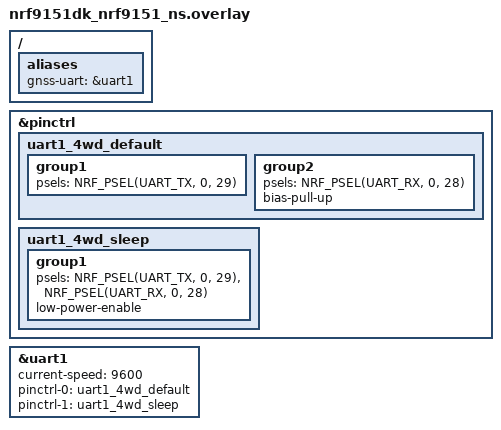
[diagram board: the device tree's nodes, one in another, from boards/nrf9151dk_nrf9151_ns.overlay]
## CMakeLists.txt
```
#
# Copyright (c) 2019 Nordic Semiconductor
#
# SPDX-License-Identifier: LicenseRef-Nordic-5-Clause
#

cmake_minimum_required(VERSION 3.20.0)

find_package(Zephyr REQUIRED HINTS $ENV{ZEPHYR_BASE})
project(gnss_sample)

zephyr_library_sources(src/main.c)
zephyr_library_sources_ifdef(CONFIG_GNSS_SAMPLE_BLE_ENABLED src/gnss_ble.c)
zephyr_library_sources_ifdef(CONFIG_GNSS_SAMPLE_UART_BRIDGE_ENABLED src/gnss_uart_bridge.c)
zephyr_library_sources_ifdef(CONFIG_GNSS_SAMPLE_MQTT_NBIOT_ENABLED src/cloud_config.c)
zephyr_library_sources_ifdef(CONFIG_GNSS_SAMPLE_MQTT_NBIOT_ENABLED src/telemetry_service.c)
zephyr_library_sources_ifdef(CONFIG_GNSS_SAMPLE_MQTT_NBIOT_ENABLED src/mqtt_nbiot_transport.c)
zephyr_library_sources_ifdef(CONFIG_GNSS_SAMPLE_CELLULAR_FALLBACK_ENABLED src/location_service.c)

zephyr_library_sources_ifdef(CONFIG_GNSS_SAMPLE_ASSISTANCE_NRF_CLOUD src/assistance.c)
zephyr_library_sources_ifdef(CONFIG_GNSS_SAMPLE_ASSISTANCE_SUPL src/assistance_supl.c)
zephyr_library_sources_ifdef(CONFIG_GNSS_SAMPLE_ASSISTANCE_MINIMAL src/assistance_minimal.c)
zephyr_library_sources_ifdef(CONFIG_GNSS_SAMPLE_ASSISTANCE_MINIMAL src/mcc_location_table.c)
```

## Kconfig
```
#
# Copyright (c) 2020 Nordic Semiconductor ASA
#
# SPDX-License-Identifier: LicenseRef-Nordic-5-Clause
#

menu "GNSS sample"

choice
	default GNSS_SAMPLE_MODE_CONTINUOUS
	prompt "Select GNSS operation mode"

config GNSS_SAMPLE_MODE_CONTINUOUS
	bool "Continuous tracking"

config GNSS_SAMPLE_MODE_PERIODIC
	bool "Periodic fixes"

config GNSS_SAMPLE_MODE_TTFF_TEST
	bool "Time-to-first-fix (TTFF) test mode"
	select GNSS_SAMPLE_NMEA_ONLY

endchoice

if GNSS_SAMPLE_MODE_PERIODIC

config GNSS_SAMPLE_PERIODIC_INTERVAL
	int "Fix interval for periodic fixes"
	range 10 65535
	default 120
	help
	  Fix interval (in seconds) for periodic fixes.

config GNSS_SAMPLE_PERIODIC_TIMEOUT
	int "Fix timeout for periodic fixes"
	range 0 65535
	default 120
	help
	  Fix timeout (in seconds) for periodic fixes.
	  If set to zero, GNSS is allowed to run indefinitely until a valid PVT estimate is produced.

endif # GNSS_SAMPLE_MODE_PERIODIC

if GNSS_SAMPLE_MODE_TTFF_TEST

config GNSS_SAMPLE_MODE_TTFF_TEST_COLD_START
	bool "Delete GNSS data before each start (cold start)"
	help
	  When enabled, deletes all stored data from GNSS to force a cold start every time GNSS is started.

config GNSS_SAMPLE_MODE_TTFF_TEST_INTERVAL
	int "Time to wait between TTFF tests in seconds"
	range 1 604800
	default 120

endif # GNSS_SAMPLE_MODE_TTFF_TEST

config GNSS_SAMPLE_NMEA_ONLY
	bool "Output only NMEA strings"
	help
	  Outputs only NMEA strings from the GNSS.

endmenu

choice
	default GNSS_SAMPLE_ASSISTANCE_NONE
	prompt "Select whether GNSS assistance is used or not"

config GNSS_SAMPLE_ASSISTANCE_NONE
	bool "Assistance not used"

config GNSS_SAMPLE_ASSISTANCE_NRF_CLOUD
	bool "Use nRF Cloud A-GNSS"
	select NRF_CLOUD_REST
	imply NRF_CLOUD_AGNSS
	select MODEM_JWT
	select MODEM_INFO
	select DATE_TIME

config GNSS_SAMPLE_ASSISTANCE_SUPL
	bool "Use SUPL assistance"
	select SUPL_CLIENT_LIB

config GNSS_SAMPLE_ASSISTANCE_MINIMAL
	bool "Use factory almanac, LTE network time and MCC based location"
	select GNSS_SAMPLE_LTE_ON_DEMAND
	select SETTINGS
	select FCB
	select FLASH
	select FLASH_MAP

endchoice

if !GNSS_SAMPLE_ASSISTANCE_NONE

config GNSS_SAMPLE_LTE_ON_DEMAND
	bool "LTE is activated only when needed to fetch A-GNSS data"
	depends on !NRF_CLOUD_PGPS
	help
	  Activates LTE only when it is needed to fetch A-GNSS data. This is not supported when
	  P-GPS is enabled.

endif # !GNSS_SAMPLE_ASSISTANCE_NONE

if GNSS_SAMPLE_ASSISTANCE_SUPL

config GNSS_SAMPLE_SUPL_HOSTNAME
	string "SUPL server hostname"
	help
	  SUPL server hostname.

config GNSS_SAMPLE_SUPL_PORT
	int "SUPL server port number"
	range 0 65535
	default 7275 if GNSS_SAMPLE_SUPL_SEC_TAG > 0
	default 7276
	help
	  SUPL server port number. The OMA UserPlane Location Protocol (ULP) port number is 7275,
	  but some servers are known to use port 7276 for non-TLS connections.

config GNSS_SAMPLE_SUPL_SEC_TAG
	int "Security tag for connection to the SUPL server"
	range 0 2147483667
	default 0
	help
	  Set a non-zero value to use TLS for connection to the SUPL server. When TLS is enabled,
	  a root CA certificate must be stored on the modem.

endif # GNSS_SAMPLE_ASSISTANCE_SUPL

if GNSS_SAMPLE_MODE_CONTINUOUS

choice
	default GNSS_SAMPLE_POWER_SAVING_DISABLED
	prompt "Select GNSS power saving mode (duty-cycling)"

config GNSS_SAMPLE_POWER_SAVING_DISABLED
	bool "No power saving"

config GNSS_SAMPLE_POWER_SAVING_MODERATE
	bool "Power saving without significant performance degradation"

config GNSS_SAMPLE_POWER_SAVING_HIGH
	bool "Power saving with acceptable performance degradation"

endchoice

endif # GNSS_SAMPLE_MODE_CONTINUOUS

config GNSS_SAMPLE_REFERENCE_LATITUDE
	string "Reference position latitude in decimal degrees"
	help
	  When set, the sample calculates the distance from the reference position for each fix.
	  Given in decimal degrees (DD), for example "61.500000".

config GNSS_SAMPLE_REFERENCE_LONGITUDE
	string "Reference position longitude in decimal degrees"
	help
	  When set, the sample calculates the distance from the reference position for each fix.
	  Given in decimal degrees (DD), for example "23.800000".

config GNSS_SAMPLE_LOW_ACCURACY
	bool "Allow low accuracy fixes"
	help
	  Allows fixes with lower accuracy.

config GNSS_SAMPLE_MIN_SATELLITES_IN_FIX
	int "Minimum satellites used in fix (0 to disable)"
	range 0 32
	default 0
	help
	  Rejects valid fixes that use fewer satellites than this threshold.
	  Set to 0 to disable filtering.

config GNSS_SAMPLE_MAX_HDOP
	int "Maximum HDOP in tenths (0 to disable)"
	range 0 1000
	default 0
	help
	  Rejects valid fixes with HDOP higher than this threshold.
	  Example: value 25 means HDOP <= 2.5 is accepted.
	  Set to 0 to disable filtering.

config GNSS_SAMPLE_BLE_ENABLED
	bool "Enable BLE streaming interface"
	depends on BT_CTLR
	select BT
	select BT_PERIPHERAL
	select BT_GATT_DYNAMIC_DB
	select BT_DEVICE_NAME_DYNAMIC
	help
	  Enables custom BLE service to stream GNSS JSON frames and accept control commands.

if GNSS_SAMPLE_BLE_ENABLED

config GNSS_SAMPLE_BLE_DEVICE_NAME
	string "BLE device name"
	default "GNSS-DK"
	help
	  BLE advertising name presented to mobile applications.

config GNSS_SAMPLE_BLE_STREAM_RATE_HZ
	int "BLE GNSS stream rate (Hz)"
	range 1 5
	default 1
	help
	  Rate of GNSS JSON notifications sent over BLE.

config GNSS_SAMPLE_BLE_TX_QUEUE_LEN
	int "BLE transmit queue length"
	range 2 32
	default 8
	help
	  Number of pending BLE payload slots. Oldest is dropped on overflow.

endif # GNSS_SAMPLE_BLE_ENABLED

config GNSS_SAMPLE_UART_BRIDGE_ENABLED
	bool "Enable UART bridge for external Bluetooth serial module"
	default y
	select SERIAL
	select UART_INTERRUPT_DRIVEN
	help
	  Streams newline-delimited GNSS JSON frames over a secondary UART and
	  accepts simple text commands from an external serial/Bluetooth module.

if GNSS_SAMPLE_UART_BRIDGE_ENABLED

config GNSS_SAMPLE_UART_BRIDGE_STREAM_RATE_HZ
	int "UART bridge GNSS stream rate (Hz)"
	range 1 5
	default 1
	help
	  Rate of GNSS JSON lines sent over the external UART bridge.

endif # GNSS_SAMPLE_UART_BRIDGE_ENABLED

config GNSS_SAMPLE_CONSOLE_OUTPUT_ENABLED
	bool "Enable periodic GNSS console output"
	default y
	help
	  Prints periodic PVT and NMEA data to the USB serial console.

config GNSS_SAMPLE_GNSS_ENABLED
	bool "Enable GNSS modem operation"
	default y
	help
	  Initializes and starts the modem GNSS engine. Disable for a modem-only
	  build that does not consume GNSS PVT or NMEA data.

config GNSS_SAMPLE_MQTT_NBIOT_ENABLED
	bool "Enable NB-IoT MQTT telemetry transport"
	select MQTT_LIB
	select NET_SOCKETS
	select NET_SOCKETS_OFFLOAD
	help
	  Adds a non-blocking NB-IoT MQTT publisher. BLE and UART transports
	  continue independently. MQTT publishes compact JSON from a location
	  priority chain: GNSS first, then cellular fallback, then last known.

config GNSS_SAMPLE_CELLULAR_FALLBACK_ENABLED
	bool "Enable cellular location fallback when GNSS has no valid fix"
	depends on GNSS_SAMPLE_MQTT_NBIOT_ENABLED
	default y
	help
	  Enables cell-tower based location estimation fallback for MQTT
	  telemetry when GNSS has no accepted valid fix. GNSS remains primary.
	  Cellular location is approximate and is marked as source=cellular.

if GNSS_SAMPLE_MQTT_NBIOT_ENABLED

if GNSS_SAMPLE_CELLULAR_FALLBACK_ENABLED

config GNSS_SAMPLE_CELLULAR_LOCATION_REQUEST_INTERVAL_SECONDS
	int "Cellular fallback request interval in seconds"
	range 15 3600
	default 120
	help
	  Minimum interval between new cellular location requests while GNSS
	  fix is not valid. Keeps NB-IoT usage bounded.

config GNSS_SAMPLE_CELLULAR_LOCATION_TIMEOUT_SECONDS
	int "Cellular fallback HTTP request timeout in seconds"
	range 10 300
	default 45
	help
	  Timeout for one cellular location lookup request to the backend API.

config GNSS_SAMPLE_CELLULAR_LOCATION_CELL_COUNT
	int "Cellular fallback requested cell count"
	range 1 15
	default 4
	help
	  Number of cells requested in %NCELLMEAS command before sending
	  data to the backend resolver.

config GNSS_SAMPLE_CELLULAR_LOCATION_API_HOSTNAME
	string "Cellular location backend hostname"
	default "example.com"
	help
	  Backend hostname that resolves cellular measurements into
	  approximate coordinates.

config GNSS_SAMPLE_CELLULAR_LOCATION_API_PORT
	int "Cellular location backend port"
	range 1 65535
	default 80

config GNSS_SAMPLE_CELLULAR_LOCATION_API_PATH
	string "Cellular location backend path"
	default "/api/cell-loc"
	help
	  HTTP path on the backend API endpoint.

config GNSS_SAMPLE_CELLULAR_LOCATION_API_AUTH_HEADER
	string "Optional Authorization header value"
	default ""
	help
	  Optional full Authorization header value, for example:
	  "Bearer eyJ...". Leave empty if not needed.

config GNSS_SAMPLE_CELLULAR_LOCATION_WORKQ_STACK_SIZE
	int "Cellular fallback worker stack size"
	default 4096

endif # GNSS_SAMPLE_CELLULAR_FALLBACK_ENABLED

config GNSS_SAMPLE_MQTT_APN
	string "NB-IoT APN"
	default "internet.m2mportal.de"
	help
	  APN expected for the default PDP context. Set matching LTE_LC/PDN
	  defaults in prj.conf so the modem uses this APN for CID 0.

config GNSS_SAMPLE_MQTT_BROKER_HOSTNAME
	string "MQTT broker hostname"
	default "test.mosquitto.org"
	help
	  MQTT broker hostname for telemetry publishing.

config GNSS_SAMPLE_MQTT_BROKER_PORT
	int "MQTT broker port"
	range 1 65535
	default 8883 if GNSS_SAMPLE_MQTT_TLS_ENABLED
	default 1883

config GNSS_SAMPLE_MQTT_TLS_ENABLED
	bool "Enable MQTT over TLS (MQTTS)"
	default y
	help
	  Enables secure MQTT transport with TLS. Recommended for NB-IoT
	  deployments where plain port 1883 may be filtered.

if GNSS_SAMPLE_MQTT_TLS_ENABLED

config GNSS_SAMPLE_MQTT_TLS_SEC_TAG
	int "Modem security tag for MQTT TLS credentials"
	default 955
	help
	  Security tag where CA certificate chain is stored in modem NVM.

config GNSS_SAMPLE_MQTT_TLS_PROVISION_CA_CERT
	bool "Provision MQTT CA certificate from firmware on boot"
	default y
	help
	  Writes/updates the CA chain in modem key storage before LTE
	  connection starts.

choice GNSS_SAMPLE_MQTT_TLS_CA_CERT_PROFILE
	prompt "MQTT TLS CA certificate profile"
	default GNSS_SAMPLE_MQTT_TLS_CA_CERT_PROFILE_MOSQUITTO
	help
	  Select which CA certificate chain is provisioned when TLS
	  provisioning is enabled.

config GNSS_SAMPLE_MQTT_TLS_CA_CERT_PROFILE_MOSQUITTO
	bool "Mosquitto test broker CA"
	help
	  CA certificate chain matching test.mosquitto.org.

config GNSS_SAMPLE_MQTT_TLS_CA_CERT_PROFILE_ISRG_ROOT_X1
	bool "ISRG Root X1 (Let's Encrypt)"
	help
	  Root CA used by many public MQTT endpoints, including blynk.cloud.

endchoice # GNSS_SAMPLE_MQTT_TLS_CA_CERT_PROFILE

endif # GNSS_SAMPLE_MQTT_TLS_ENABLED

config GNSS_SAMPLE_MQTT_BROKER_FALLBACK_ENABLED
	bool "Enable MQTT broker fallback"
	default y
	help
	  When enabled, firmware switches to a fallback broker after repeated
	  MQTT connect timeouts.

if GNSS_SAMPLE_MQTT_BROKER_FALLBACK_ENABLED

config GNSS_SAMPLE_MQTT_BROKER_FALLBACK_HOSTNAME
	string "Fallback MQTT broker hostname"
	default "broker.hivemq.com"

config GNSS_SAMPLE_MQTT_BROKER_FALLBACK_PORT
	int "Fallback MQTT broker port"
	range 1 65535
	default 8883 if GNSS_SAMPLE_MQTT_TLS_ENABLED
	default 1883

config GNSS_SAMPLE_MQTT_FAILOVER_AFTER_TIMEOUTS
	int "Failover after consecutive MQTT connect timeouts"
	range 1 20
	default 3

endif # GNSS_SAMPLE_MQTT_BROKER_FALLBACK_ENABLED

config GNSS_SAMPLE_MQTT_CLIENT_ID
	string "MQTT client ID"
	default "nrf9151-001"

config GNSS_SAMPLE_MQTT_USERNAME
	string "MQTT username (optional)"
	default ""
	help
	  Optional MQTT username. For Blynk MQTT use "device".

config GNSS_SAMPLE_MQTT_PASSWORD
	string "MQTT password/token (optional)"
	default ""
	help
	  Optional MQTT password/token. Leave empty to disable password auth.

config GNSS_SAMPLE_MQTT_DEVICE_ID
	string "Telemetry device ID"
	default "nrf9151-001"

config GNSS_SAMPLE_MQTT_TOPIC
	string "MQTT telemetry topic"
	default "devices/nrf9151-001/telemetry"

config GNSS_SAMPLE_MQTT_SUBSCRIBE_TOPIC
	string "MQTT subscribe topic (optional)"
	default ""
	help
	  Optional topic subscription for downlink commands, for example
	  "downlink/#" on Blynk MQTT.

config GNSS_SAMPLE_MQTT_RETAIN_MESSAGES
	bool "Publish MQTT telemetry with retain flag"
	default n
	help
	  When enabled, the broker stores the last published telemetry payload
	  on the topic and delivers it immediately to new subscribers.

config GNSS_SAMPLE_MQTT_PUBLISH_INTERVAL_SECONDS
	int "Minimum MQTT publish interval in seconds"
	range 10 86400
	default 60
	help
	  Minimum interval between MQTT publishes. Keep this conservative for
	  limited NB-IoT SIM data volume.

config GNSS_SAMPLE_MQTT_RETRY_BACKOFF_SECONDS
	int "MQTT retry backoff in seconds"
	range 10 3600
	default 60

config GNSS_SAMPLE_MQTT_REGISTRATION_TIMEOUT_SECONDS
	int "NB-IoT registration status log interval in seconds"
	range 10 3600
	default 120

config GNSS_SAMPLE_MQTT_SEARCH_RECOVERY_SECONDS
	int "NB-IoT search recovery interval in seconds"
	range 30 3600
	default 240
	help
	  If LTE remains unregistered/searching for this long, the firmware
	  will trigger an automatic offline/reconnect recovery cycle.

config GNSS_SAMPLE_MQTT_CONNECT_TIMEOUT_SECONDS
	int "MQTT connect timeout in seconds"
	range 10 300
	default 120
	help
	  Time to wait for CONNACK after MQTT connect attempt. NB-IoT links can
	  be higher-latency than Wi-Fi/LTE-M, so use a conservative timeout.

config GNSS_SAMPLE_MQTT_QUEUE_LEN
	int "MQTT telemetry queue length"
	range 1 8
	default 2
	help
	  Number of valid-fix telemetry samples that can wait for MQTT. Oldest
	  samples are dropped on overflow to avoid stale positions.

config GNSS_SAMPLE_MQTT_BATTERY_PERCENT
	int "Static battery percent included in MQTT JSON (-1 disables)"
	range -1 100
	default -1
	help
	  Placeholder for boards without a battery gauge wired yet. Set to -1
	  to omit battery from compact MQTT JSON.

config GNSS_SAMPLE_MQTT_STACK_SIZE
	int "MQTT worker thread stack size"
	default 4096

config GNSS_SAMPLE_MQTT_THREAD_PRIORITY
	int "MQTT worker thread priority"
	default 7

config GNSS_SAMPLE_TELEMETRY_SERVER_HOST
	string "Telemetry server host (UDP/CoAP)"
	default ""
	help
	  Backend host used for low-data request/response telemetry.

config GNSS_SAMPLE_TELEMETRY_SERVER_PORT
	int "Telemetry server port"
	range 1 65535
	default 9000

config GNSS_SAMPLE_TELEMETRY_PROTOCOL
	string "Telemetry protocol"
	default "udp"
	help
	  Supported values in current implementation: udp, coap.

config GNSS_SAMPLE_TELEMETRY_PUBLISH_INTERVAL_SECONDS
	int "Telemetry interval in seconds"
	range 30 86400
	default 600

config GNSS_SAMPLE_GNSS_TIMEOUT_SECONDS
	int "GNSS timeout in seconds"
	range 10 3600
	default 60

config GNSS_SAMPLE_DATA_MODE_DEFAULT
	string "Default data mode"
	default "auto"
	help
	  Supported values: auto, tn_only, ntn_only.

config GNSS_SAMPLE_TN_ENABLED_DEFAULT
	bool "Enable TN by default"
	default y

config GNSS_SAMPLE_NTN_ENABLED_DEFAULT
	bool "Enable NTN fallback by default"
	default y

config GNSS_SAMPLE_TN_UNAVAILABLE_TIMEOUT_SECONDS
	int "TN unavailable timeout in seconds"
	range 60 86400
	default 300
	help
	  TN is considered unavailable when registration/network failures
	  persist this long continuously.

config GNSS_SAMPLE_NTN_MIN_SEND_INTERVAL_SECONDS
	int "Minimum NTN send interval in seconds"
	range 300 2592000
	default 3600
	help
	  Minimum spacing between NTN payload attempts to protect the low
	  monthly NTN quota.

config GNSS_SAMPLE_NTN_MAX_PAYLOAD_BYTES_DEFAULT
	int "Maximum NTN payload size in bytes"
	range 64 512
	default 200

config GNSS_SAMPLE_MONTHLY_NTN_BYTE_LIMIT_DEFAULT
	int "Monthly NTN byte limit"
	range 1024 500000
	default 50000

config GNSS_SAMPLE_CONFIG_VERSION_DEFAULT
	int "Default configuration version"
	range 0 100000
	default 1

config GNSS_SAMPLE_AUTH_TOKEN_DEFAULT
	string "Default auth token/shared secret"
	default ""

config GNSS_SAMPLE_MAX_PAYLOAD_BYTES_DEFAULT
	int "Default max payload bytes"
	range 64 1200
	default 300

config GNSS_SAMPLE_ENABLE_DEBUG_LOGS_DEFAULT
	bool "Enable debug logs by default"
	default n

config GNSS_SAMPLE_MQTT_SYNC_ENABLED
	bool "Enable MQTT retained config sync"
	default y

config GNSS_SAMPLE_MQTT_SYNC_INTERVAL_SECONDS
	int "MQTT config sync interval in seconds"
	range 300 172800
	default 21600

config GNSS_SAMPLE_MQTT_SYNC_FORCE_IN_NTN
	bool "Allow MQTT config sync in NTN mode"
	default n

config GNSS_SAMPLE_NTN_MIN_INTERVAL_SECONDS
	int "Minimum telemetry interval in NTN mode"
	range 300 86400
	default 3600

config GNSS_SAMPLE_TELEMETRY_BACKOFF_BASE_SECONDS
	int "Base backoff for telemetry failures in seconds"
	range 5 3600
	default 60

config GNSS_SAMPLE_TELEMETRY_BACKOFF_MAX_SECONDS
	int "Maximum backoff for telemetry failures in seconds"
	range 10 86400
	default 3600

endif # GNSS_SAMPLE_MQTT_NBIOT_ENABLED

if GNSS_SAMPLE_ASSISTANCE_MINIMAL && GNSS_SAMPLE_LOW_ACCURACY

config GNSS_SAMPLE_ASSISTANCE_REFERENCE_ALT
	int "Reference altitude for 3-sat first fix in meters"
	range -32767 32767
	default -32767
	help
	  Reference altitude for 3-sat first fix in meters above the reference ellipsoid surface.
	  The default value -32767 implies that reference altitude is not injected.

endif # GNSS_SAMPLE_ASSISTANCE_MINIMAL && GNSS_SAMPLE_LOW_ACCURACY

menu "Zephyr Kernel"
source "Kconfig.zephyr"
endmenu

module = GNSS_SAMPLE
module-str = GNSS sample
source "$(ZEPHYR_BASE)/subsys/logging/Kconfig.template.log_config"
```

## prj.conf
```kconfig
#
# Copyright (c) 2019 Nordic Semiconductor ASA
#
# SPDX-License-Identifier: LicenseRef-Nordic-5-Clause
#

# TF-M config
CONFIG_TFM_PROFILE_TYPE_MINIMAL=y

# General
CONFIG_FPU=y
CONFIG_NRF_MODEM_LIB=y
CONFIG_STDOUT_CONSOLE=y
CONFIG_UART_INTERRUPT_DRIVEN=y
CONFIG_PICOLIBC_IO_FLOAT=y
CONFIG_LOG=y
CONFIG_LOG_MODE_IMMEDIATE=y
CONFIG_SNTP=n
CONFIG_REBOOT=y
CONFIG_SETTINGS=y
CONFIG_SETTINGS_NVS=y
CONFIG_NVS=y
CONFIG_FLASH=y
CONFIG_FLASH_MAP=y
CONFIG_PM_PARTITION_SIZE_SETTINGS_STORAGE=0x8000
CONFIG_SHELL=y
CONFIG_SHELL_BACKEND_SERIAL=y
CONFIG_SHELL_CMD_BUFF_SIZE=256

# GNSS sample
CONFIG_GNSS_SAMPLE_ASSISTANCE_NRF_CLOUD=n

# LTE Link Control
CONFIG_LTE_LINK_CONTROL=y
CONFIG_LTE_NETWORK_MODE_NBIOT_GPS=y
CONFIG_LTE_MODE_PREFERENCE_AUTO=y
CONFIG_LTE_LC_SYSTEM_MODE_MODULE=y
CONFIG_LTE_LC_FUNCTIONAL_MODE_MODULE=y
CONFIG_LTE_LC_PDN_MODULE=y
CONFIG_LTE_LC_PDN_DEFAULTS_OVERRIDE=y
CONFIG_LTE_LC_PDN_DEFAULT_APN="internet.m2mportal.de"
CONFIG_LTE_LC_PDN_DEFAULT_FAM_IPV4V6=y
CONFIG_LTE_LC_PSM_MODULE=y
CONFIG_LTE_PSM_REQ=y
# PSM requested periodic TAU 8 hours
CONFIG_LTE_PSM_REQ_RPTAU="00101000"
# PSM requested active time 6 seconds
CONFIG_LTE_PSM_REQ_RAT="00000011"

# The USB VCOM is used by the Zephyr shell for local test commands such as
# `ble_send`.  Keep direct nrf_modem_at_cmd() calls available to the app, but
# do not attach the AT host input handler to this same UART.
CONFIG_AT_HOST_LIBRARY=n

# External serial bridge to the 4WD board Bluetooth module.
CONFIG_GNSS_SAMPLE_UART_BRIDGE_ENABLED=y
CONFIG_GNSS_SAMPLE_CONSOLE_OUTPUT_ENABLED=y
CONFIG_GNSS_SAMPLE_GNSS_ENABLED=y
CONFIG_GNSS_SAMPLE_UART_BRIDGE_STREAM_RATE_HZ=1

# Networking
CONFIG_NETWORKING=y
CONFIG_NET_SOCKETS_OFFLOAD=y
CONFIG_NET_SOCKETS=y
CONFIG_NET_IPV4=y
# Disable native network stack to save some memory
CONFIG_NET_NATIVE=n

# NB-IoT MQTT telemetry transport.
CONFIG_GNSS_SAMPLE_MQTT_NBIOT_ENABLED=n
CONFIG_GNSS_SAMPLE_MQTT_APN="internet.m2mportal.de"
CONFIG_GNSS_SAMPLE_MQTT_BROKER_HOSTNAME="broker.hivemq.com"
CONFIG_GNSS_SAMPLE_MQTT_BROKER_PORT=1883
CONFIG_GNSS_SAMPLE_MQTT_TLS_ENABLED=n
CONFIG_GNSS_SAMPLE_MQTT_BROKER_FALLBACK_ENABLED=n
CONFIG_GNSS_SAMPLE_MQTT_CLIENT_ID="nrf9151-001"
CONFIG_GNSS_SAMPLE_MQTT_USERNAME=""
CONFIG_GNSS_SAMPLE_MQTT_PASSWORD=""
CONFIG_GNSS_SAMPLE_MQTT_DEVICE_ID="nrf9151-001"
CONFIG_GNSS_SAMPLE_MQTT_TOPIC="devices/nrf9151-001/config-sync-unused"
CONFIG_GNSS_SAMPLE_MQTT_RETAIN_MESSAGES=n
CONFIG_GNSS_SAMPLE_MQTT_PUBLISH_INTERVAL_SECONDS=600
CONFIG_GNSS_SAMPLE_MQTT_RETRY_BACKOFF_SECONDS=60
CONFIG_MQTT_KEEPALIVE=120

# Hybrid low-data defaults.
CONFIG_GNSS_SAMPLE_TELEMETRY_SERVER_HOST=""
CONFIG_GNSS_SAMPLE_TELEMETRY_SERVER_PORT=9000
CONFIG_GNSS_SAMPLE_TELEMETRY_PROTOCOL="udp"
CONFIG_GNSS_SAMPLE_TELEMETRY_PUBLISH_INTERVAL_SECONDS=600
CONFIG_GNSS_SAMPLE_GNSS_TIMEOUT_SECONDS=60
CONFIG_GNSS_SAMPLE_DATA_MODE_DEFAULT="auto"
CONFIG_GNSS_SAMPLE_TN_ENABLED_DEFAULT=y
CONFIG_GNSS_SAMPLE_NTN_ENABLED_DEFAULT=y
CONFIG_GNSS_SAMPLE_TN_UNAVAILABLE_TIMEOUT_SECONDS=300
CONFIG_GNSS_SAMPLE_NTN_MIN_SEND_INTERVAL_SECONDS=3600
CONFIG_GNSS_SAMPLE_NTN_MAX_PAYLOAD_BYTES_DEFAULT=200
CONFIG_GNSS_SAMPLE_MONTHLY_NTN_BYTE_LIMIT_DEFAULT=50000
CONFIG_GNSS_SAMPLE_CONFIG_VERSION_DEFAULT=1
CONFIG_GNSS_SAMPLE_AUTH_TOKEN_DEFAULT=""
CONFIG_GNSS_SAMPLE_MAX_PAYLOAD_BYTES_DEFAULT=300
CONFIG_GNSS_SAMPLE_ENABLE_DEBUG_LOGS_DEFAULT=n
CONFIG_GNSS_SAMPLE_MQTT_SYNC_ENABLED=n
CONFIG_GNSS_SAMPLE_MQTT_SYNC_INTERVAL_SECONDS=21600
CONFIG_GNSS_SAMPLE_MQTT_SYNC_FORCE_IN_NTN=n
CONFIG_GNSS_SAMPLE_TELEMETRY_BACKOFF_BASE_SECONDS=60
CONFIG_GNSS_SAMPLE_TELEMETRY_BACKOFF_MAX_SECONDS=3600

# OpenCellID/cellular resolver fallback removed.
CONFIG_GNSS_SAMPLE_CELLULAR_FALLBACK_ENABLED=n

# Memory and stack configuration
CONFIG_HEAP_MEM_POOL_SIZE=8192
CONFIG_MAIN_STACK_SIZE=4096
CONFIG_SYSTEM_WORKQUEUE_STACK_SIZE=1536
```

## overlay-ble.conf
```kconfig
#
# BLE streaming overlay for BLE-capable Nordic boards.
# Example:
# west build -b nrf52840dk/nrf52840 -- -DEXTRA_CONF_FILE=overlay-ble.conf
#

CONFIG_GNSS_SAMPLE_BLE_ENABLED=y
CONFIG_GNSS_SAMPLE_BLE_DEVICE_NAME="GNSS-DK"
CONFIG_GNSS_SAMPLE_BLE_STREAM_RATE_HZ=1
CONFIG_GNSS_SAMPLE_BLE_TX_QUEUE_LEN=8

CONFIG_BT=y
CONFIG_BT_PERIPHERAL=y
CONFIG_BT_DEVICE_NAME_DYNAMIC=y
CONFIG_BT_MAX_CONN=1
CONFIG_BT_SETTINGS=y
CONFIG_SETTINGS=y
CONFIG_BT_SMP=y
CONFIG_BT_SIGNING=n
CONFIG_BT_GATT_CLIENT=n
CONFIG_BT_CTLR_PHY_2M=n
```

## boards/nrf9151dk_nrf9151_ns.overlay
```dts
/* Route the application UART bridge to the nRF9151 SMA DK header pins.
 * Wire P0.29/TX to the 4WD board Bluetooth RX net, and P0.28/RX to Bluetooth TX.
 */

/ {
	aliases {
		gnss-uart = &uart1;
	};
};

&pinctrl {
	uart1_4wd_default: uart1_4wd_default {
		group1 {
			psels = <NRF_PSEL(UART_TX, 0, 29)>;
		};

		group2 {
			psels = <NRF_PSEL(UART_RX, 0, 28)>;
			bias-pull-up;
		};
	};

	uart1_4wd_sleep: uart1_4wd_sleep {
		group1 {
			psels = <NRF_PSEL(UART_TX, 0, 29)>,
				<NRF_PSEL(UART_RX, 0, 28)>;
			low-power-enable;
		};
	};
};

&uart1 {
	status = "okay";
	current-speed = <9600>;
	pinctrl-0 = <&uart1_4wd_default>;
	pinctrl-1 = <&uart1_4wd_sleep>;
	pinctrl-names = "default", "sleep";
};
```

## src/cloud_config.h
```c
/*
 * Copyright (c) 2026
 *
 * SPDX-License-Identifier: LicenseRef-Nordic-5-Clause
 */

#ifndef CLOUD_CONFIG_H_
#define CLOUD_CONFIG_H_

#include <stdbool.h>
#include <stdint.h>
#include <modem/lte_lc.h>

#ifdef __cplusplus
extern "C" {
#endif

#define CLOUD_CONFIG_DEVICE_ID_MAX_LEN 64
#define CLOUD_CONFIG_HOST_MAX_LEN 96
#define CLOUD_CONFIG_PROTOCOL_MAX_LEN 8
#define CLOUD_CONFIG_TOPIC_MAX_LEN 128
#define CLOUD_CONFIG_USERNAME_MAX_LEN 64
#define CLOUD_CONFIG_PASSWORD_MAX_LEN 128
#define CLOUD_CONFIG_TOKEN_MAX_LEN 128
#define CLOUD_CONFIG_APN_MAX_LEN 64
#define CLOUD_CONFIG_LTE_MODE_MAX_LEN 32
#define CLOUD_CONFIG_DATA_MODE_MAX_LEN 16

struct cloud_runtime_config {
	char device_id[CLOUD_CONFIG_DEVICE_ID_MAX_LEN];
	char server_host[CLOUD_CONFIG_HOST_MAX_LEN];
	uint16_t server_port;
	char protocol[CLOUD_CONFIG_PROTOCOL_MAX_LEN];
	char telemetry_protocol[CLOUD_CONFIG_PROTOCOL_MAX_LEN];
	uint32_t publish_interval_sec;
	uint32_t gnss_timeout_sec;
	char data_mode[CLOUD_CONFIG_DATA_MODE_MAX_LEN];
	bool tn_enabled;
	bool ntn_enabled;
	uint32_t tn_unavailable_timeout_sec;
	uint32_t ntn_min_send_interval_sec;
	uint16_t ntn_max_payload_bytes;
	uint32_t monthly_ntn_byte_limit;
	uint32_t config_version;
	char auth_token[CLOUD_CONFIG_TOKEN_MAX_LEN];
	uint16_t max_payload_bytes;
	bool enable_debug_logs;

	char mqtt_host[CLOUD_CONFIG_HOST_MAX_LEN];
	uint16_t mqtt_port;
	char mqtt_username[CLOUD_CONFIG_USERNAME_MAX_LEN];
	char mqtt_password[CLOUD_CONFIG_PASSWORD_MAX_LEN];
	int32_t mqtt_tls_sec_tag;
	uint32_t mqtt_sync_interval_sec;
	bool mqtt_sync_enabled;
	bool mqtt_sync_force_in_ntn;

	char apn[CLOUD_CONFIG_APN_MAX_LEN];
	char lte_mode[CLOUD_CONFIG_LTE_MODE_MAX_LEN];
};

int cloud_config_init(void);
const struct cloud_runtime_config *cloud_config_get(void);
const char *cloud_config_device_id_get(void);

int cloud_config_set(const char *key, const char *value);
int cloud_config_save(void);
bool cloud_config_is_dirty(void);
bool cloud_config_reboot_required(void);

int cloud_config_get_lte_mode(enum lte_lc_system_mode *mode,
			      enum lte_lc_system_mode_preference *pref);

int cloud_config_apply_mqtt_retained(const char *json, size_t len, bool *applied_newer);

#ifdef __cplusplus
}
#endif

#endif /* CLOUD_CONFIG_H_ */
```

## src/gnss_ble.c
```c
/*
 * Copyright (c) 2026
 *
 * SPDX-License-Identifier: LicenseRef-Nordic-5-Clause
 */

#include "gnss_ble.h"

#include <stdio.h>
#include <stdlib.h>
#include <string.h>
#include <zephyr/kernel.h>
#include <zephyr/sys/atomic.h>
#include <zephyr/sys/util.h>
#include <zephyr/logging/log.h>
#include <zephyr/bluetooth/bluetooth.h>
#include <zephyr/bluetooth/conn.h>
#include <zephyr/bluetooth/gatt.h>
#include <zephyr/bluetooth/uuid.h>
#include <zephyr/settings/settings.h>

LOG_MODULE_DECLARE(gnss_sample, CONFIG_GNSS_SAMPLE_LOG_LEVEL);

#define GNSS_BLE_JSON_BUF_LEN 768
#define GNSS_BLE_CMD_MAX_LEN 64

/* 6b6f6f00-39f0-4d47-9c30-47c0c53b3d01 */
#define BT_UUID_GNSS_SERVICE_VAL \
	BT_UUID_128_ENCODE(0x6b6f6f00, 0x39f0, 0x4d47, 0x9c30, 0x47c0c53b3d01)
/* 6b6f6f01-39f0-4d47-9c30-47c0c53b3d01 */
#define BT_UUID_GNSS_TX_VAL \
	BT_UUID_128_ENCODE(0x6b6f6f01, 0x39f0, 0x4d47, 0x9c30, 0x47c0c53b3d01)
/* 6b6f6f02-39f0-4d47-9c30-47c0c53b3d01 */
#define BT_UUID_GNSS_RX_VAL \
	BT_UUID_128_ENCODE(0x6b6f6f02, 0x39f0, 0x4d47, 0x9c30, 0x47c0c53b3d01)

static struct bt_uuid_128 gnss_service_uuid = BT_UUID_INIT_128(BT_UUID_GNSS_SERVICE_VAL);
static struct bt_uuid_128 gnss_tx_uuid = BT_UUID_INIT_128(BT_UUID_GNSS_TX_VAL);
static struct bt_uuid_128 gnss_rx_uuid = BT_UUID_INIT_128(BT_UUID_GNSS_RX_VAL);

static struct bt_conn *current_conn;
static atomic_t notify_enabled;
static atomic_t stream_enabled = ATOMIC_INIT(1);
static atomic_t stream_rate_hz = ATOMIC_INIT(CONFIG_GNSS_SAMPLE_BLE_STREAM_RATE_HZ);
static atomic_t ble_dropped;

static char last_gga[NRF_MODEM_GNSS_NMEA_MAX_LEN];
static char last_rmc[NRF_MODEM_GNSS_NMEA_MAX_LEN];

struct ble_line {
	char data[GNSS_BLE_JSON_BUF_LEN];
};

K_MSGQ_DEFINE(ble_tx_queue, sizeof(struct ble_line), CONFIG_GNSS_SAMPLE_BLE_TX_QUEUE_LEN, 4);
static struct k_work ble_tx_work;

static struct bt_conn_cb conn_callbacks;

static ssize_t gnss_rx_write(struct bt_conn *conn,
			     const struct bt_gatt_attr *attr,
			     const void *buf,
			     uint16_t len,
			     uint16_t offset,
			     uint8_t flags);
static void ccc_cfg_changed(const struct bt_gatt_attr *attr, uint16_t value);

BT_GATT_SERVICE_DEFINE(gnss_service,
	BT_GATT_PRIMARY_SERVICE(&gnss_service_uuid),
	BT_GATT_CHARACTERISTIC(&gnss_tx_uuid.uuid,
			       BT_GATT_CHRC_NOTIFY,
			       BT_GATT_PERM_NONE,
			       NULL, NULL, NULL),
	BT_GATT_CCC(ccc_cfg_changed,
		    BT_GATT_PERM_READ | BT_GATT_PERM_WRITE),
	BT_GATT_CHARACTERISTIC(&gnss_rx_uuid.uuid,
			       BT_GATT_CHRC_WRITE | BT_GATT_CHRC_WRITE_WITHOUT_RESP,
			       BT_GATT_PERM_WRITE_ENCRYPT,
			       NULL, gnss_rx_write, NULL),
);

static void ccc_cfg_changed(const struct bt_gatt_attr *attr, uint16_t value)
{
	ARG_UNUSED(attr);

	atomic_set(&notify_enabled, (value == BT_GATT_CCC_NOTIFY) ? 1 : 0);
	LOG_INF("BLE notifications %s", atomic_get(&notify_enabled) ? "enabled" : "disabled");
}

static int ble_enqueue_line(const char *line)
{
	struct ble_line item = { 0 };
	size_t copy_len = MIN(strlen(line), sizeof(item.data) - 1U);
	memcpy(item.data, line, copy_len);

	int err = k_msgq_put(&ble_tx_queue, &item, K_NO_WAIT);
	if (err) {
		struct ble_line dropped;
		if (k_msgq_get(&ble_tx_queue, &dropped, K_NO_WAIT) == 0) {
			atomic_inc(&ble_dropped);
			(void)k_msgq_put(&ble_tx_queue, &item, K_NO_WAIT);
		}
	}

	k_work_submit(&ble_tx_work);
	return 0;
}

static void ble_tx_work_fn(struct k_work *work)
{
	ARG_UNUSED(work);

	if (!current_conn || !atomic_get(&notify_enabled) || !atomic_get(&stream_enabled)) {
		return;
	}

	struct ble_line item;
	while (k_msgq_get(&ble_tx_queue, &item, K_NO_WAIT) == 0) {
		int err = bt_gatt_notify(current_conn, &gnss_service.attrs[2], item.data,
					 strlen(item.data));
		if (err) {
			LOG_WRN("BLE notify failed: %d", err);
			break;
		}
	}
}

static void connected(struct bt_conn *conn, uint8_t err)
{
	if (err) {
		LOG_WRN("BLE connect failed: %u", err);
		return;
	}

	current_conn = bt_conn_ref(conn);
	LOG_INF("BLE connected");
	(void)bt_conn_set_security(conn, BT_SECURITY_L2);
}

static void disconnected(struct bt_conn *conn, uint8_t reason)
{
	ARG_UNUSED(reason);

	if (current_conn) {
		bt_conn_unref(current_conn);
		current_conn = NULL;
	}

	atomic_clear(&notify_enabled);
	LOG_INF("BLE disconnected");
}

static bool nmea_is_sentence(const char *line, const char *prefix)
{
	return (strncmp(line, prefix, strlen(prefix)) == 0);
}

static bool pvt_datetime_valid(const struct nrf_modem_gnss_datetime *datetime)
{
	return datetime &&
	       datetime->year >= 2024 &&
	       datetime->month >= 1 && datetime->month <= 12 &&
	       datetime->day >= 1 && datetime->day <= 31 &&
	       datetime->hour <= 23 &&
	       datetime->minute <= 59 &&
	       datetime->seconds <= 60;
}

void gnss_ble_set_last_nmea(const struct nrf_modem_gnss_nmea_data_frame *nmea)
{
	if (!nmea) {
		return;
	}

	if (nmea_is_sentence(nmea->nmea_str, "$GPGGA") || nmea_is_sentence(nmea->nmea_str, "$GNGGA")) {
		strncpy(last_gga, nmea->nmea_str, sizeof(last_gga) - 1U);
		last_gga[sizeof(last_gga) - 1U] = '\0';
	} else if (nmea_is_sentence(nmea->nmea_str, "$GPRMC") ||
		   nmea_is_sentence(nmea->nmea_str, "$GNRMC")) {
		strncpy(last_rmc, nmea->nmea_str, sizeof(last_rmc) - 1U);
		last_rmc[sizeof(last_rmc) - 1U] = '\0';
	}
}

static ssize_t gnss_rx_write(struct bt_conn *conn,
			     const struct bt_gatt_attr *attr,
			     const void *buf,
			     uint16_t len,
			     uint16_t offset,
			     uint8_t flags)
{
	ARG_UNUSED(conn);
	ARG_UNUSED(attr);
	ARG_UNUSED(offset);
	ARG_UNUSED(flags);

	char cmd[GNSS_BLE_CMD_MAX_LEN] = {0};
	size_t copy = MIN((size_t)len, sizeof(cmd) - 1U);
	memcpy(cmd, buf, copy);

	if (strcmp(cmd, "START_STREAM") == 0) {
		atomic_set(&stream_enabled, 1);
		gnss_ble_notify_status("STREAM_STARTED", "Streaming enabled", "");
		return len;
	}

	if (strcmp(cmd, "STOP_STREAM") == 0) {
		atomic_set(&stream_enabled, 0);
		gnss_ble_notify_status("STREAM_STOPPED", "Streaming disabled", "");
		return len;
	}

	if (strncmp(cmd, "SET_RATE:", 9) == 0) {
		long rate = strtol(cmd + 9, NULL, 10);
		if (rate >= 1 && rate <= 5) {
			atomic_set(&stream_rate_hz, (int)rate);
			gnss_ble_notify_status("RATE_UPDATED", "Stream rate updated", cmd + 9);
		} else {
			gnss_ble_notify_status("INVALID_RATE", "SET_RATE must be between 1 and 5",
					       cmd + 9);
		}
		return len;
	}

	if (strcmp(cmd, "REQUEST_STATUS") == 0) {
		gnss_ble_notify_status("STATUS", "Status requested", "");
		return len;
	}

	gnss_ble_notify_status("UNKNOWN_COMMAND", "Unsupported command", cmd);
	return len;
}

void gnss_ble_notify_status(const char *code, const char *message, const char *details)
{
	char buf[GNSS_BLE_JSON_BUF_LEN];
	snprintk(buf, sizeof(buf),
		 "{\"type\":\"status\",\"code\":\"%s\",\"message\":\"%s\",\"details\":\"%s\"}\n",
		 code ? code : "", message ? message : "", details ? details : "");
	(void)ble_enqueue_line(buf);
}

void gnss_ble_notify_pvt(const struct nrf_modem_gnss_pvt_data_frame *pvt,
			 uint8_t tracked,
			 uint8_t used,
			 uint8_t unhealthy,
			 const struct gnss_ble_metrics *metrics)
{
	static int64_t last_sent_ms;
	int hz = atomic_get(&stream_rate_hz);
	int64_t now_ms = k_uptime_get();
	int64_t min_period = 1000 / MAX(hz, 1);

	if (!pvt || !atomic_get(&stream_enabled)) {
		return;
	}

	if ((now_ms - last_sent_ms) < min_period) {
		return;
	}

	last_sent_ms = now_ms;

	char json[GNSS_BLE_JSON_BUF_LEN];
	bool valid = (pvt->flags & NRF_MODEM_GNSS_PVT_FLAG_FIX_VALID) != 0;
	uint32_t accepted = metrics ? metrics->fixes_accepted : 0U;
	uint32_t rejected = metrics ? metrics->fixes_rejected : 0U;
	uint32_t nmea_d = metrics ? metrics->nmea_dropped : 0U;
	char timestamp[25] = {0};
	bool have_timestamp = false;

	if (pvt_datetime_valid(&pvt->datetime)) {
		snprintk(timestamp, sizeof(timestamp),
			 "%04u-%02u-%02uT%02u:%02u:%02uZ",
			 pvt->datetime.year, pvt->datetime.month, pvt->datetime.day,
			 pvt->datetime.hour, pvt->datetime.minute, pvt->datetime.seconds);
		have_timestamp = true;
	}

	if (valid) {
		if (have_timestamp) {
			snprintk(json, sizeof(json),
				 "{\"ts_ms\":%lld,\"timestamp\":\"%s\",\"fix_valid\":true,"
				 "\"lat\":%.06f,\"lon\":%.06f,\"accuracy_m\":%.01f,"
				 "\"alt_m\":%.01f,\"alt_acc_m\":%.01f,"
				 "\"speed_mps\":%.01f,\"speed_acc_mps\":%.01f,"
				 "\"v_speed_mps\":%.01f,\"v_speed_acc_mps\":%.01f,"
				 "\"heading_deg\":%.01f,\"heading_acc_deg\":%.01f,"
				 "\"pdop\":%.01f,\"hdop\":%.01f,\"vdop\":%.01f,\"tdop\":%.01f,"
				 "\"tracked\":%u,\"used\":%u,\"unhealthy\":%u,"
				 "\"nmea_gga\":\"%s\",\"nmea_rmc\":\"%s\","
				 "\"counters\":{\"accepted\":%u,\"rejected\":%u,\"nmea_dropped\":%u,"
				 "\"ble_dropped\":%u}}\n",
				 now_ms, timestamp,
				 pvt->latitude, pvt->longitude, (double)pvt->accuracy,
				 (double)pvt->altitude, (double)pvt->altitude_accuracy,
				 (double)pvt->speed, (double)pvt->speed_accuracy,
				 (double)pvt->vertical_speed, (double)pvt->vertical_speed_accuracy,
				 (double)pvt->heading, (double)pvt->heading_accuracy,
				 (double)pvt->pdop, (double)pvt->hdop, (double)pvt->vdop, (double)pvt->tdop,
				 tracked, used, unhealthy,
				 last_gga, last_rmc, accepted, rejected, nmea_d,
				 (uint32_t)atomic_get(&ble_dropped));
		} else {
			snprintk(json, sizeof(json),
				 "{\"ts_ms\":%lld,\"fix_valid\":true,\"lat\":%.06f,\"lon\":%.06f,"
				 "\"accuracy_m\":%.01f,\"alt_m\":%.01f,\"alt_acc_m\":%.01f,"
				 "\"speed_mps\":%.01f,\"speed_acc_mps\":%.01f,"
				 "\"v_speed_mps\":%.01f,\"v_speed_acc_mps\":%.01f,"
				 "\"heading_deg\":%.01f,\"heading_acc_deg\":%.01f,"
				 "\"pdop\":%.01f,\"hdop\":%.01f,\"vdop\":%.01f,\"tdop\":%.01f,"
				 "\"tracked\":%u,\"used\":%u,\"unhealthy\":%u,"
				 "\"nmea_gga\":\"%s\",\"nmea_rmc\":\"%s\","
				 "\"counters\":{\"accepted\":%u,\"rejected\":%u,\"nmea_dropped\":%u,"
				 "\"ble_dropped\":%u}}\n",
				 now_ms,
				 pvt->latitude, pvt->longitude, (double)pvt->accuracy,
				 (double)pvt->altitude, (double)pvt->altitude_accuracy,
				 (double)pvt->speed, (double)pvt->speed_accuracy,
				 (double)pvt->vertical_speed, (double)pvt->vertical_speed_accuracy,
				 (double)pvt->heading, (double)pvt->heading_accuracy,
				 (double)pvt->pdop, (double)pvt->hdop, (double)pvt->vdop, (double)pvt->tdop,
				 tracked, used, unhealthy,
				 last_gga, last_rmc, accepted, rejected, nmea_d,
				 (uint32_t)atomic_get(&ble_dropped));
		}
	} else {
		if (have_timestamp) {
			snprintk(json, sizeof(json),
				 "{\"ts_ms\":%lld,\"timestamp\":\"%s\",\"fix_valid\":false,"
				 "\"lat\":null,\"lon\":null,\"alt_m\":null,"
				 "\"accuracy_m\":%.01f,\"alt_acc_m\":%.01f,"
				 "\"speed_mps\":%.01f,\"speed_acc_mps\":%.01f,"
				 "\"v_speed_mps\":%.01f,\"v_speed_acc_mps\":%.01f,"
				 "\"heading_deg\":%.01f,\"heading_acc_deg\":%.01f,"
				 "\"pdop\":%.01f,\"hdop\":%.01f,\"vdop\":%.01f,\"tdop\":%.01f,"
				 "\"tracked\":%u,\"used\":%u,\"unhealthy\":%u,"
				 "\"nmea_gga\":\"%s\",\"nmea_rmc\":\"%s\","
				 "\"counters\":{\"accepted\":%u,\"rejected\":%u,\"nmea_dropped\":%u,"
				 "\"ble_dropped\":%u}}\n",
				 now_ms, timestamp,
				 (double)pvt->accuracy, (double)pvt->altitude_accuracy,
				 (double)pvt->speed, (double)pvt->speed_accuracy,
				 (double)pvt->vertical_speed, (double)pvt->vertical_speed_accuracy,
				 (double)pvt->heading, (double)pvt->heading_accuracy,
				 (double)pvt->pdop, (double)pvt->hdop, (double)pvt->vdop, (double)pvt->tdop,
				 tracked, used, unhealthy,
				 last_gga, last_rmc, accepted, rejected, nmea_d,
				 (uint32_t)atomic_get(&ble_dropped));
		} else {
			snprintk(json, sizeof(json),
				 "{\"ts_ms\":%lld,\"fix_valid\":false,\"lat\":null,\"lon\":null,\"alt_m\":null,"
				 "\"accuracy_m\":%.01f,\"alt_acc_m\":%.01f,"
				 "\"speed_mps\":%.01f,\"speed_acc_mps\":%.01f,"
				 "\"v_speed_mps\":%.01f,\"v_speed_acc_mps\":%.01f,"
				 "\"heading_deg\":%.01f,\"heading_acc_deg\":%.01f,"
				 "\"pdop\":%.01f,\"hdop\":%.01f,\"vdop\":%.01f,\"tdop\":%.01f,"
				 "\"tracked\":%u,\"used\":%u,\"unhealthy\":%u,"
				 "\"nmea_gga\":\"%s\",\"nmea_rmc\":\"%s\","
				 "\"counters\":{\"accepted\":%u,\"rejected\":%u,\"nmea_dropped\":%u,"
				 "\"ble_dropped\":%u}}\n",
				 now_ms,
				 (double)pvt->accuracy, (double)pvt->altitude_accuracy,
				 (double)pvt->speed, (double)pvt->speed_accuracy,
				 (double)pvt->vertical_speed, (double)pvt->vertical_speed_accuracy,
				 (double)pvt->heading, (double)pvt->heading_accuracy,
				 (double)pvt->pdop, (double)pvt->hdop, (double)pvt->vdop, (double)pvt->tdop,
				 tracked, used, unhealthy,
				 last_gga, last_rmc, accepted, rejected, nmea_d,
				 (uint32_t)atomic_get(&ble_dropped));
		}
	}

	(void)ble_enqueue_line(json);
}

bool gnss_ble_stream_enabled(void)
{
	return atomic_get(&stream_enabled) != 0;
}

uint8_t gnss_ble_stream_rate_hz(void)
{
	return (uint8_t)atomic_get(&stream_rate_hz);
}

uint32_t gnss_ble_dropped_count(void)
{
	return (uint32_t)atomic_get(&ble_dropped);
}

int gnss_ble_init(void)
{
	int err;

	conn_callbacks.connected = connected;
	conn_callbacks.disconnected = disconnected;
	bt_conn_cb_register(&conn_callbacks);
	k_work_init(&ble_tx_work, ble_tx_work_fn);

	err = bt_enable(NULL);
	if (err) {
		LOG_ERR("Failed to enable BLE: %d", err);
		return err;
	}

	if (IS_ENABLED(CONFIG_SETTINGS)) {
		settings_load();
	}

	err = bt_set_name(CONFIG_GNSS_SAMPLE_BLE_DEVICE_NAME);
	if (err) {
		LOG_WRN("Failed to set BLE name: %d", err);
	}

	const struct bt_data ad[] = {
		BT_DATA_BYTES(BT_DATA_FLAGS, (BT_LE_AD_GENERAL | BT_LE_AD_NO_BREDR)),
		BT_DATA_BYTES(BT_DATA_UUID128_ALL, BT_UUID_GNSS_SERVICE_VAL),
	};
	const struct bt_data sd[] = {
		BT_DATA(BT_DATA_NAME_COMPLETE, CONFIG_GNSS_SAMPLE_BLE_DEVICE_NAME,
			sizeof(CONFIG_GNSS_SAMPLE_BLE_DEVICE_NAME) - 1),
	};

	err = bt_le_adv_start(BT_LE_ADV_CONN_FAST_1, ad, ARRAY_SIZE(ad), sd, ARRAY_SIZE(sd));
	if (err) {
		LOG_ERR("Failed to start BLE advertising: %d", err);
		return err;
	}

	LOG_INF("BLE advertising started as %s", CONFIG_GNSS_SAMPLE_BLE_DEVICE_NAME);
	return 0;
}
```

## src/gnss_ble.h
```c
/*
 * Copyright (c) 2026
 *
 * SPDX-License-Identifier: LicenseRef-Nordic-5-Clause
 */

#ifndef GNSS_BLE_H_
#define GNSS_BLE_H_

#include <stdint.h>
#include <stdbool.h>
#include <nrf_modem_gnss.h>

#ifdef __cplusplus
extern "C" {
#endif

struct gnss_ble_metrics {
	uint32_t fixes_accepted;
	uint32_t fixes_rejected;
	uint32_t nmea_dropped;
};

int gnss_ble_init(void);

void gnss_ble_set_last_nmea(const struct nrf_modem_gnss_nmea_data_frame *nmea);

void gnss_ble_notify_pvt(const struct nrf_modem_gnss_pvt_data_frame *pvt,
			 uint8_t tracked,
			 uint8_t used,
			 uint8_t unhealthy,
			 const struct gnss_ble_metrics *metrics);

void gnss_ble_notify_status(const char *code, const char *message, const char *details);

bool gnss_ble_stream_enabled(void);
uint8_t gnss_ble_stream_rate_hz(void);
uint32_t gnss_ble_dropped_count(void);

#ifdef __cplusplus
}
#endif

#endif /* GNSS_BLE_H_ */
```

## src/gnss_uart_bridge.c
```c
/*
 * Copyright (c) 2026
 *
 * SPDX-License-Identifier: LicenseRef-Nordic-5-Clause
 */

#include "gnss_uart_bridge.h"

#include <stdio.h>
#include <stdlib.h>
#include <string.h>
#include <zephyr/device.h>
#include <zephyr/drivers/uart.h>
#include <zephyr/kernel.h>
#include <zephyr/logging/log.h>
#include <zephyr/sys/atomic.h>
#include <zephyr/sys/util.h>

LOG_MODULE_DECLARE(gnss_sample, CONFIG_GNSS_SAMPLE_LOG_LEVEL);

#define GNSS_UART_NODE DT_ALIAS(gnss_uart)

#if !DT_NODE_HAS_STATUS(GNSS_UART_NODE, okay)
#error "GNSS UART bridge requires a devicetree alias named gnss-uart"
#endif

#define JSON_BUF_LEN 512
#define CMD_BUF_LEN 64

static const struct device *const bridge_uart = DEVICE_DT_GET(GNSS_UART_NODE);

struct uart_cmd {
	char data[CMD_BUF_LEN];
};

static atomic_t stream_enabled = ATOMIC_INIT(1);
static atomic_t stream_rate_hz = ATOMIC_INIT(CONFIG_GNSS_SAMPLE_UART_BRIDGE_STREAM_RATE_HZ);
static atomic_t rx_command_count;
static atomic_t rx_overflow_count;

static char last_gga[NRF_MODEM_GNSS_NMEA_MAX_LEN];
static char last_rmc[NRF_MODEM_GNSS_NMEA_MAX_LEN];
static char rx_line[CMD_BUF_LEN];
static size_t rx_line_len;
static int64_t last_publish_ms;

K_MSGQ_DEFINE(uart_cmd_queue, sizeof(struct uart_cmd), 4, 4);
static struct k_work uart_cmd_work;

static void uart_write_str(const char *s)
{
	while (*s != '\0') {
		uart_poll_out(bridge_uart, *s++);
	}
}

static void json_append_escaped(char *buf, size_t len, const char *value)
{
	size_t used = strnlen(buf, len);

	if (used >= len) {
		return;
	}

	for (const char *p = value; *p != '\0'; ++p) {
		if (used >= len - 1U) {
			return;
		}

		if (*p == '\\' || *p == '"') {
			if (used < len - 2U) {
				buf[used++] = '\\';
				buf[used++] = *p;
				buf[used] = '\0';
			}
		} else if (*p == '\r') {
			continue;
		} else if (*p == '\n') {
			continue;
		} else {
			buf[used++] = *p;
			buf[used] = '\0';
		}
	}
}

static bool nmea_is_sentence(const char *line, const char *prefix)
{
	return strncmp(line, prefix, strlen(prefix)) == 0;
}

void gnss_uart_bridge_set_last_nmea(const struct nrf_modem_gnss_nmea_data_frame *nmea)
{
	if (!nmea) {
		return;
	}

	if (nmea_is_sentence(nmea->nmea_str, "$GPGGA") ||
	    nmea_is_sentence(nmea->nmea_str, "$GNGGA")) {
		strncpy(last_gga, nmea->nmea_str, sizeof(last_gga) - 1U);
		last_gga[sizeof(last_gga) - 1U] = '\0';
	} else if (nmea_is_sentence(nmea->nmea_str, "$GPRMC") ||
		   nmea_is_sentence(nmea->nmea_str, "$GNRMC")) {
		strncpy(last_rmc, nmea->nmea_str, sizeof(last_rmc) - 1U);
		last_rmc[sizeof(last_rmc) - 1U] = '\0';
	}
}

static void append_optional_nmea(char *json, size_t len)
{
	if (last_gga[0] != '\0') {
		strncat(json, ",\"nmea_gga\":\"", len - strlen(json) - 1U);
		json_append_escaped(json, len, last_gga);
		strncat(json, "\"", len - strlen(json) - 1U);
	}

	if (last_rmc[0] != '\0') {
		strncat(json, ",\"nmea_rmc\":\"", len - strlen(json) - 1U);
		json_append_escaped(json, len, last_rmc);
		strncat(json, "\"", len - strlen(json) - 1U);
	}
}

void gnss_uart_bridge_publish_status(const char *code, const char *message, const char *details)
{
	char json[JSON_BUF_LEN];

	snprintk(json, sizeof(json),
		 "{\"type\":\"status\",\"ts_ms\":%lld,\"code\":\"%s\",\"message\":\"%s\",\"details\":\"",
		 k_uptime_get(), code ? code : "", message ? message : "");
	json_append_escaped(json, sizeof(json), details ? details : "");
	strncat(json, "\"}\n", sizeof(json) - strlen(json) - 1U);
	uart_write_str(json);
}

void gnss_uart_bridge_send_text(const char *text)
{
	if (!text) {
		return;
	}

	uart_write_str(text);
	uart_write_str("\r\n");
}

static void handle_command(char *cmd)
{
	atomic_inc(&rx_command_count);

	if (strcmp(cmd, "PING") == 0) {
		gnss_uart_bridge_publish_status("PONG", "UART bridge is alive", "");
		return;
	}

	if (strcmp(cmd, "START_STREAM") == 0) {
		atomic_set(&stream_enabled, 1);
		gnss_uart_bridge_publish_status("STREAM_STARTED", "Streaming enabled", "");
		return;
	}

	if (strcmp(cmd, "STOP_STREAM") == 0) {
		atomic_set(&stream_enabled, 0);
		gnss_uart_bridge_publish_status("STREAM_STOPPED", "Streaming disabled", "");
		return;
	}

	if (strncmp(cmd, "SET_RATE:", 9) == 0) {
		long rate = strtol(cmd + 9, NULL, 10);

		if (rate >= 1 && rate <= 5) {
			atomic_set(&stream_rate_hz, (int)rate);
			gnss_uart_bridge_publish_status("RATE_UPDATED", "Stream rate updated", cmd + 9);
		} else {
			gnss_uart_bridge_publish_status("INVALID_RATE", "SET_RATE must be 1..5", cmd + 9);
		}
		return;
	}

	if (strcmp(cmd, "REQUEST_STATUS") == 0) {
		char details[96];

		snprintk(details, sizeof(details), "stream=%s rate_hz=%u rx_commands=%u rx_overflows=%u",
			 atomic_get(&stream_enabled) ? "on" : "off",
			 (uint8_t)atomic_get(&stream_rate_hz),
			 (uint32_t)atomic_get(&rx_command_count),
			 (uint32_t)atomic_get(&rx_overflow_count));
		gnss_uart_bridge_publish_status("STATUS", "UART bridge status", details);
		return;
	}

	gnss_uart_bridge_publish_status("UNKNOWN_COMMAND", "Unsupported UART command", cmd);
}

static void uart_cmd_work_fn(struct k_work *work)
{
	ARG_UNUSED(work);

	struct uart_cmd cmd;

	while (k_msgq_get(&uart_cmd_queue, &cmd, K_NO_WAIT) == 0) {
		handle_command(cmd.data);
	}
}

static void uart_irq_callback(const struct device *dev, void *user_data)
{
	ARG_UNUSED(user_data);

	while (uart_irq_update(dev) && uart_irq_rx_ready(dev)) {
		uint8_t c;

		while (uart_fifo_read(dev, &c, 1) == 1) {
			if (c == '\r' || c == '\n') {
				if (rx_line_len > 0U) {
					struct uart_cmd cmd = {0};

					memcpy(cmd.data, rx_line, rx_line_len);
					cmd.data[rx_line_len] = '\0';
					if (k_msgq_put(&uart_cmd_queue, &cmd, K_NO_WAIT) != 0) {
						atomic_inc(&rx_overflow_count);
					} else {
						k_work_submit(&uart_cmd_work);
					}
					rx_line_len = 0U;
				}
				continue;
			}

			if (rx_line_len < sizeof(rx_line) - 1U) {
				rx_line[rx_line_len++] = (char)c;
			} else {
				rx_line_len = 0U;
				atomic_inc(&rx_overflow_count);
			}
		}
	}
}

int gnss_uart_bridge_init(void)
{
	if (!device_is_ready(bridge_uart)) {
		LOG_ERR("GNSS UART bridge device is not ready");
		return -ENODEV;
	}

	k_work_init(&uart_cmd_work, uart_cmd_work_fn);

	uart_irq_callback_user_data_set(bridge_uart, uart_irq_callback, NULL);
	uart_irq_rx_enable(bridge_uart);

	gnss_uart_bridge_publish_status("BOOT", "GNSS UART bridge ready",
					  "pins=nRF9151 P0.29 TX/P0.28 RX baud=9600");
	return 0;
}

void gnss_uart_bridge_publish_pvt(const struct nrf_modem_gnss_pvt_data_frame *pvt,
					  uint8_t tracked,
					  uint8_t used,
					  uint8_t unhealthy,
					  const struct gnss_uart_bridge_metrics *metrics)
{
	if (!atomic_get(&stream_enabled)) {
		return;
	}

	int64_t now = k_uptime_get();
	uint8_t rate_hz = (uint8_t)atomic_get(&stream_rate_hz);
	int64_t min_interval_ms = 1000 / MAX(rate_hz, 1U);

	if (last_publish_ms != 0 && (now - last_publish_ms) < min_interval_ms) {
		return;
	}
	last_publish_ms = now;

	bool fix_valid = (pvt->flags & NRF_MODEM_GNSS_PVT_FLAG_FIX_VALID) != 0;
	char json[JSON_BUF_LEN];
	int len;

	if (fix_valid) {
		len = snprintk(json, sizeof(json),
			"{\"ts_ms\":%lld,\"fix_valid\":true,"
			"\"lat\":%.06f,\"lon\":%.06f,\"alt_m\":%.01f,"
			"\"speed_mps\":%.01f,\"heading_deg\":%.01f,\"accuracy_m\":%.01f,\"hdop\":%.01f,"
			"\"tracked\":%u,\"used\":%u,\"unhealthy\":%u,"
			"\"counters\":{\"accepted\":%u,\"rejected\":%u,\"nmea_dropped\":%u,"
			"\"uart_rx_commands\":%u,\"uart_rx_overflows\":%u}",
			now, pvt->latitude, pvt->longitude, (double)pvt->altitude,
			(double)pvt->speed, (double)pvt->heading, (double)pvt->accuracy,
			(double)pvt->hdop, tracked, used, unhealthy,
			metrics ? metrics->fixes_accepted : 0U,
			metrics ? metrics->fixes_rejected : 0U,
			metrics ? metrics->nmea_dropped : 0U,
			(uint32_t)atomic_get(&rx_command_count),
			(uint32_t)atomic_get(&rx_overflow_count));
	} else {
		len = snprintk(json, sizeof(json),
			"{\"ts_ms\":%lld,\"fix_valid\":false,"
			"\"lat\":null,\"lon\":null,\"alt_m\":null,"
			"\"speed_mps\":null,\"heading_deg\":null,\"accuracy_m\":%.01f,\"hdop\":%.01f,"
			"\"tracked\":%u,\"used\":%u,\"unhealthy\":%u,"
			"\"counters\":{\"accepted\":%u,\"rejected\":%u,\"nmea_dropped\":%u,"
			"\"uart_rx_commands\":%u,\"uart_rx_overflows\":%u}",
			now, (double)pvt->accuracy, (double)pvt->hdop, tracked, used, unhealthy,
			metrics ? metrics->fixes_accepted : 0U,
			metrics ? metrics->fixes_rejected : 0U,
			metrics ? metrics->nmea_dropped : 0U,
			(uint32_t)atomic_get(&rx_command_count),
			(uint32_t)atomic_get(&rx_overflow_count));
	}

	if (len < 0 || len >= sizeof(json)) {
		return;
	}

	append_optional_nmea(json, sizeof(json));
	strncat(json, "}\n", sizeof(json) - strlen(json) - 1U);
	uart_write_str(json);
}

bool gnss_uart_bridge_stream_enabled(void)
{
	return atomic_get(&stream_enabled) != 0;
}

uint8_t gnss_uart_bridge_stream_rate_hz(void)
{
	return (uint8_t)atomic_get(&stream_rate_hz);
}

uint32_t gnss_uart_bridge_rx_command_count(void)
{
	return (uint32_t)atomic_get(&rx_command_count);
}

uint32_t gnss_uart_bridge_rx_overflow_count(void)
{
	return (uint32_t)atomic_get(&rx_overflow_count);
}
```
